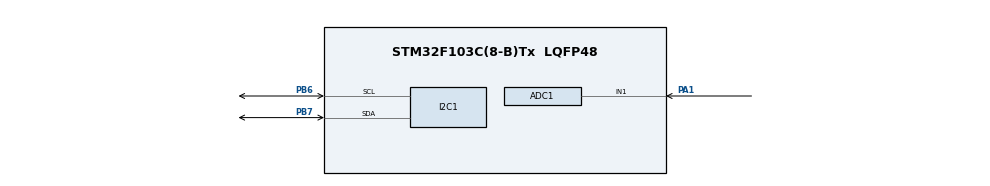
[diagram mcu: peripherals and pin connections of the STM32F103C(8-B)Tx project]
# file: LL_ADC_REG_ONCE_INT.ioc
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ADC1.Channel-0\#ChannelRegularConversion=ADC_CHANNEL_1
ADC1.NbrOfConversionFlag=1
ADC1.Rank-0\#ChannelRegularConversion=1
ADC1.SamplingTime-0\#ChannelRegularConversion=ADC_SAMPLETIME_1CYCLE_5
ADC1.master=1
I2C1.I2C_Mode=I2C_Standard
Mcu.Family=STM32F1
Mcu.Name=STM32F103C(8-B)Tx
Mcu.Package=LQFP48
NVIC.ADC1_2_IRQn=true\:0\:0\:false\:false\:true\:true\:true
NVIC.PriorityGroup=NVIC_PRIORITYGROUP_4
PA1.Signal=ADCx_IN1
PA13.Mode=Serial_Wire
PA13.Signal=SYS_JTMS-SWDIO
PA14.Mode=Serial_Wire
PA14.Signal=SYS_JTCK-SWCLK
PB6.Mode=I2C
PB6.Signal=I2C1_SCL
PB7.Mode=I2C
PB7.Signal=I2C1_SDA
PD0-OSC_IN.Mode=HSE-External-Oscillator
PD0-OSC_IN.Signal=RCC_OSC_IN
PD1-OSC_OUT.Mode=HSE-External-Oscillator
PD1-OSC_OUT.Signal=RCC_OSC_OUT
ProjectManager.HeapSize=0x200
ProjectManager.StackSize=0x400
ProjectManager.TargetToolchain=MDK-ARM V5
RCC.ADCPresc=RCC_ADCPCLK2_DIV6
RCC.AHBFreq_Value=72000000
RCC.APB1CLKDivider=RCC_HCLK_DIV2
RCC.APB1Freq_Value=36000000
RCC.APB1TimFreq_Value=72000000
RCC.APB2Freq_Value=72000000
RCC.APB2TimFreq_Value=72000000
RCC.HCLKFreq_Value=72000000
RCC.PLLMUL=RCC_PLL_MUL9
RCC.PLLSourceVirtual=RCC_PLLSOURCE_HSE
RCC.SYSCLKFreq_VALUE=72000000
RCC.SYSCLKSource=RCC_SYSCLKSOURCE_PLLCLK
RCC.USBFreq_Value=72000000
SH.ADCx_IN1.0=ADC1_IN1,IN1
board=custom

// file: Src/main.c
/* USER CODE BEGIN Header */
/**
  ******************************************************************************
  * @file           : main.c
  * @brief          : Main program body
  ******************************************************************************
  ** This notice applies to any and all portions of this file
  * that are not between comment pairs USER CODE BEGIN and
  * USER CODE END. Other portions of this file, whether
  * inserted by the user or by software development tools
  * are owned by their respective copyright owners.
  *
  * COPYRIGHT(c) 2019 STMicroelectronics
  *
  * Redistribution and use in source and binary forms, with or without modification,
  * are permitted provided that the following conditions are met:
  *   1. Redistributions of source code must retain the above copyright notice,
  *      this list of conditions and the following disclaimer.
  *   2. Redistributions in binary form must reproduce the above copyright notice,
  *      this list of conditions and the following disclaimer in the documentation
  *      and/or other materials provided with the distribution.
  *   3. Neither the name of STMicroelectronics nor the names of its contributors
  *      may be used to endorse or promote products derived from this software
  *      without specific prior written permission.
  *
  * THIS SOFTWARE IS PROVIDED BY THE COPYRIGHT HOLDERS AND CONTRIBUTORS "AS IS"
  * AND ANY EXPRESS OR IMPLIED WARRANTIES, INCLUDING, BUT NOT LIMITED TO, THE
  * IMPLIED WARRANTIES OF MERCHANTABILITY AND FITNESS FOR A PARTICULAR PURPOSE ARE
  * DISCLAIMED. IN NO EVENT SHALL THE COPYRIGHT HOLDER OR CONTRIBUTORS BE LIABLE
  * FOR ANY DIRECT, INDIRECT, INCIDENTAL, SPECIAL, EXEMPLARY, OR CONSEQUENTIAL
  * DAMAGES (INCLUDING, BUT NOT LIMITED TO, PROCUREMENT OF SUBSTITUTE GOODS OR
  * SERVICES; LOSS OF USE, DATA, OR PROFITS; OR BUSINESS INTERRUPTION) HOWEVER
  * CAUSED AND ON ANY THEORY OF LIABILITY, WHETHER IN CONTRACT, STRICT LIABILITY,
  * OR TORT (INCLUDING NEGLIGENCE OR OTHERWISE) ARISING IN ANY WAY OUT OF THE USE
  * OF THIS SOFTWARE, EVEN IF ADVISED OF THE POSSIBILITY OF SUCH DAMAGE.
  *
  ******************************************************************************
  */
/* USER CODE END Header */

#include "main.h"

/* USER CODE BEGIN Includes */
#include "lcd.h"
#include <stdio.h>
/* USER CODE END Includes */

/* USER CODE BEGIN PV */
__IO uint8_t fl_adc;
/* USER CODE END PV */

void SystemClock_Config(void);
static void MX_GPIO_Init(void);
static void MX_I2C1_Init(void);
static void MX_ADC1_Init(void);

int main(void)
{
  /* USER CODE BEGIN 1 */
  __IO uint32_t wait_loop_index = 0;
  __IO uint16_t ADC_Data;
  __IO uint16_t ADC_mVolt;
  char str01[15];
  /* USER CODE END 1 */

  /* MCU Configuration--------------------------------------------------------*/

  /* Reset of all peripherals, Initializes the Flash interface and the Systick. */

  LL_APB2_GRP1_EnableClock(LL_APB2_GRP1_PERIPH_AFIO);
  LL_APB1_GRP1_EnableClock(LL_APB1_GRP1_PERIPH_PWR);

  NVIC_SetPriorityGrouping(NVIC_PRIORITYGROUP_4);

  /* System interrupt init*/

  /** NOJTAG: JTAG-DP Disabled and SW-DP Enabled
  */
  LL_GPIO_AF_Remap_SWJ_NOJTAG();

  /* Configure the system clock */
  SystemClock_Config();

  /* Initialize all configured peripherals */
  MX_GPIO_Init();
  MX_I2C1_Init();
  MX_ADC1_Init();
  /* USER CODE BEGIN 2 */
  LCD_ini();
  LL_ADC_EnableIT_EOS(ADC1);
  LL_ADC_Enable(ADC1);
  wait_loop_index = ((LL_ADC_DELAY_ENABLE_CALIB_ADC_CYCLES * 32) >> 1);
  while(wait_loop_index != 0)
  {
    wait_loop_index--;
  }
  LL_ADC_StartCalibration(ADC1);
  while (LL_ADC_IsCalibrationOnGoing(ADC1) != 0) {}
  LCD_String("ADC");
  LCD_SetPos(0,1);
  LCD_String("Regular Once");
  LCD_SetPos(0,2);
  LCD_String("Intrrupt");
  /* USER CODE END 2 */

  /* Infinite loop */
  while (1)
  {

    /* USER CODE BEGIN 3 */
    LL_ADC_REG_StartConversionSWStart(ADC1);
    while (!fl_adc)  {}
    fl_adc = 0;
    ADC_Data = LL_ADC_REG_ReadConversionData12(ADC1);
    ADC_mVolt = __LL_ADC_CALC_DATA_TO_VOLTAGE((uint32_t)3275, ADC_Data, LL_ADC_RESOLUTION_12B);
    sprintf(str01,"%.2fv",(float)ADC_mVolt/1000.);
    LCD_SetPos(0,3);
    LCD_String(str01);
    LL_mDelay(100);
  }
  /* USER CODE END 3 */
}

void SystemClock_Config(void)
{
  LL_FLASH_SetLatency(LL_FLASH_LATENCY_2);

   if(LL_FLASH_GetLatency() != LL_FLASH_LATENCY_2)
  {
    Error_Handler();
  }
  LL_RCC_HSE_Enable();

   /* Wait till HSE is ready */
  while(LL_RCC_HSE_IsReady() != 1)
  {

  }
  LL_RCC_PLL_ConfigDomain_SYS(LL_RCC_PLLSOURCE_HSE_DIV_1, LL_RCC_PLL_MUL_9);
  LL_RCC_PLL_Enable();

   /* Wait till PLL is ready */
  while(LL_RCC_PLL_IsReady() != 1)
  {

  }
  LL_RCC_SetAHBPrescaler(LL_RCC_SYSCLK_DIV_1);
  LL_RCC_SetAPB1Prescaler(LL_RCC_APB1_DIV_2);
  LL_RCC_SetAPB2Prescaler(LL_RCC_APB2_DIV_1);
  LL_RCC_SetSysClkSource(LL_RCC_SYS_CLKSOURCE_PLL);

   /* Wait till System clock is ready */
  while(LL_RCC_GetSysClkSource() != LL_RCC_SYS_CLKSOURCE_STATUS_PLL)
  {

  }
  LL_Init1msTick(72000000);
  LL_SYSTICK_SetClkSource(LL_SYSTICK_CLKSOURCE_HCLK);
  LL_SetSystemCoreClock(72000000);
  LL_RCC_SetADCClockSource(LL_RCC_ADC_CLKSRC_PCLK2_DIV_6);
}

static void MX_ADC1_Init(void)
{

  LL_ADC_InitTypeDef ADC_InitStruct = {0};
  LL_ADC_CommonInitTypeDef ADC_CommonInitStruct = {0};
  LL_ADC_REG_InitTypeDef ADC_REG_InitStruct = {0};

  LL_GPIO_InitTypeDef GPIO_InitStruct = {0};

  /* Peripheral clock enable */
  LL_APB2_GRP1_EnableClock(LL_APB2_GRP1_PERIPH_ADC1);

  LL_APB2_GRP1_EnableClock(LL_APB2_GRP1_PERIPH_GPIOA);
  /**ADC1 GPIO Configuration
  PA1   ------> ADC1_IN1
  */
  GPIO_InitStruct.Pin = LL_GPIO_PIN_1;
  GPIO_InitStruct.Mode = LL_GPIO_MODE_ANALOG;
  LL_GPIO_Init(GPIOA, &GPIO_InitStruct);

  /* ADC1 interrupt Init */
  NVIC_SetPriority(ADC1_2_IRQn, NVIC_EncodePriority(NVIC_GetPriorityGrouping(),0, 0));
  NVIC_EnableIRQ(ADC1_2_IRQn);

  /** Common config
  */
  ADC_InitStruct.DataAlignment = LL_ADC_DATA_ALIGN_RIGHT;
  ADC_InitStruct.SequencersScanMode = LL_ADC_SEQ_SCAN_DISABLE;
  LL_ADC_Init(ADC1, &ADC_InitStruct);
  ADC_CommonInitStruct.Multimode = LL_ADC_MULTI_INDEPENDENT;
  LL_ADC_CommonInit(__LL_ADC_COMMON_INSTANCE(ADC1), &ADC_CommonInitStruct);
  ADC_REG_InitStruct.TriggerSource = LL_ADC_REG_TRIG_SOFTWARE;
  ADC_REG_InitStruct.SequencerLength = LL_ADC_REG_SEQ_SCAN_DISABLE;
  ADC_REG_InitStruct.SequencerDiscont = LL_ADC_REG_SEQ_DISCONT_DISABLE;
  ADC_REG_InitStruct.ContinuousMode = LL_ADC_REG_CONV_SINGLE;
  ADC_REG_InitStruct.DMATransfer = LL_ADC_REG_DMA_TRANSFER_NONE;
  LL_ADC_REG_Init(ADC1, &ADC_REG_InitStruct);
  /** Configure Regular Channel
  */
  LL_ADC_REG_SetSequencerRanks(ADC1, LL_ADC_REG_RANK_1, LL_ADC_CHANNEL_1);
  LL_ADC_SetChannelSamplingTime(ADC1, LL_ADC_CHANNEL_1, LL_ADC_SAMPLINGTIME_1CYCLE_5);

}

static void MX_I2C1_Init(void)
{

  LL_I2C_InitTypeDef I2C_InitStruct = {0};

  LL_GPIO_InitTypeDef GPIO_InitStruct = {0};

  LL_APB2_GRP1_EnableClock(LL_APB2_GRP1_PERIPH_GPIOB);
  /**I2C1 GPIO Configuration
  PB6   ------> I2C1_SCL
  PB7   ------> I2C1_SDA
  */
  GPIO_InitStruct.Pin = LL_GPIO_PIN_6|LL_GPIO_PIN_7;
  GPIO_InitStruct.Mode = LL_GPIO_MODE_ALTERNATE;
  GPIO_InitStruct.Speed = LL_GPIO_SPEED_FREQ_HIGH;
  GPIO_InitStruct.OutputType = LL_GPIO_OUTPUT_OPENDRAIN;
  LL_GPIO_Init(GPIOB, &GPIO_InitStruct);

  /* Peripheral clock enable */
  LL_APB1_GRP1_EnableClock(LL_APB1_GRP1_PERIPH_I2C1);

  /** I2C Initialization
  */
  LL_I2C_DisableOwnAddress2(I2C1);
  LL_I2C_DisableGeneralCall(I2C1);
  LL_I2C_EnableClockStretching(I2C1);
  I2C_InitStruct.PeripheralMode = LL_I2C_MODE_I2C;
  I2C_InitStruct.ClockSpeed = 100000;
  I2C_InitStruct.DutyCycle = LL_I2C_DUTYCYCLE_2;
  I2C_InitStruct.OwnAddress1 = 0;
  I2C_InitStruct.TypeAcknowledge = LL_I2C_ACK;
  I2C_InitStruct.OwnAddrSize = LL_I2C_OWNADDRESS1_7BIT;
  LL_I2C_Init(I2C1, &I2C_InitStruct);
  LL_I2C_SetOwnAddress2(I2C1, 0);

}

static void MX_GPIO_Init(void)
{

  /* GPIO Ports Clock Enable */
  LL_APB2_GRP1_EnableClock(LL_APB2_GRP1_PERIPH_GPIOD);
  LL_APB2_GRP1_EnableClock(LL_APB2_GRP1_PERIPH_GPIOA);
  LL_APB2_GRP1_EnableClock(LL_APB2_GRP1_PERIPH_GPIOB);

}

/* USER CODE BEGIN 4 */
void ADC_ConvCpltCallback(void)
{
  fl_adc = 1;
}
/* USER CODE END 4 */

void Error_Handler(void)
{
}

/************************ (C) COPYRIGHT STMicroelectronics *****END OF FILE****/
